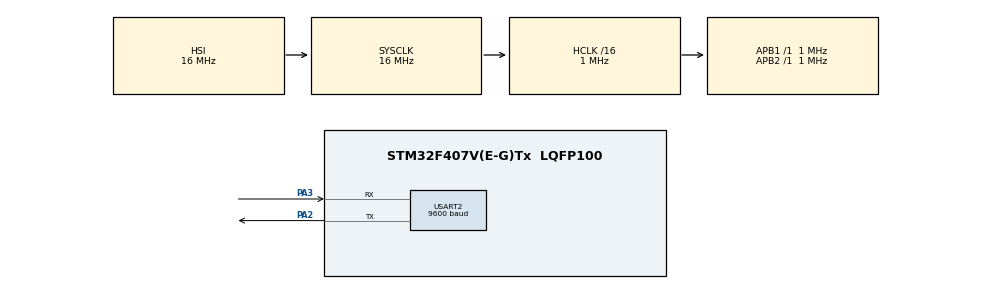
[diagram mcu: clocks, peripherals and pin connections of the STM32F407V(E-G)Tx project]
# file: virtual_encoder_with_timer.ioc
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Mcu.Family=STM32F4
Mcu.Name=STM32F407V(E-G)Tx
Mcu.Package=LQFP100
NVIC.PriorityGroup=NVIC_PRIORITYGROUP_4
NVIC.TIM4_IRQn=true\:0\:0\:false\:true\:true\:1\:true\:true\:true
NVIC.TIM6_DAC_IRQn=true\:0\:0\:false\:true\:true\:2\:true\:true\:true
NVIC.USART2_IRQn=true\:0\:0\:false\:true\:true\:3\:true\:true\:true
PA13.Mode=Serial_Wire
PA13.Signal=SYS_JTMS-SWDIO
PA14.Mode=Serial_Wire
PA14.Signal=SYS_JTCK-SWCLK
PA2.Mode=Asynchronous
PA2.Signal=USART2_TX
PA3.Mode=Asynchronous
PA3.Signal=USART2_RX
ProjectManager.HeapSize=0x200
ProjectManager.StackSize=0x400
ProjectManager.TargetToolchain=STM32CubeIDE
RCC.AHBCLKDivider=RCC_SYSCLK_DIV16
RCC.AHBFreq_Value=1000000
RCC.APB1Freq_Value=1000000
RCC.APB1TimFreq_Value=1000000
RCC.APB2Freq_Value=1000000
RCC.APB2TimFreq_Value=1000000
RCC.CortexFreq_Value=1000000
RCC.HCLKFreq_Value=1000000
RCC.HSE_VALUE=25000000
RCC.HSI_VALUE=16000000
RCC.LSE_VALUE=32768
RCC.SYSCLKFreq_VALUE=16000000
RCC.VCOOutputFreq_Value=192000000
TIM4.AutoReloadPreload=TIM_AUTORELOAD_PRELOAD_ENABLE
TIM4.Period=1000 - 1
TIM4.Prescaler=1000 - 1
TIM6.Period=5000 - 1
TIM6.Prescaler=1000 - 1
USART2.BaudRate=9600
USART2.VirtualMode=VM_ASYNC
VP_TIM4_VS_ClockSourceINT.Mode=Internal
VP_TIM6_VS_ClockSourceINT.Mode=Enable_Timer
board=custom

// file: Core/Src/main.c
/* USER CODE BEGIN Header */
/**
  ******************************************************************************
  * @file           : main.c
  * @brief          : Main program body
  ******************************************************************************
  * @attention
  *
  * Copyright (c) 2025 STMicroelectronics.
  * All rights reserved.
  *
  * This software is licensed under terms that can be found in the LICENSE file
  * in the root directory of this software component.
  * If no LICENSE file comes with this software, it is provided AS-IS.
  *
  ******************************************************************************
  */
/* USER CODE END Header */
#include "main.h"

TIM_HandleTypeDef htim4;
TIM_HandleTypeDef htim6;

UART_HandleTypeDef huart2;

/* USER CODE BEGIN PV */
volatile int32_t virtual_encoder_count = 0;
char buffer[50];
uint8_t rx_data;
/* USER CODE END PV */

void SystemClock_Config(void);
static void MX_GPIO_Init(void);
static void MX_TIM4_Init(void);
static void MX_TIM6_Init(void);
static void MX_USART2_UART_Init(void);
static void MX_NVIC_Init(void);

int main(void)
{

  /* MCU Configuration--------------------------------------------------------*/

  /* Reset of all peripherals, Initializes the Flash interface and the Systick. */
  HAL_Init();

  /* Configure the system clock */
  SystemClock_Config();

  /* Initialize all configured peripherals */
  MX_GPIO_Init();
  MX_TIM4_Init();
  MX_TIM6_Init();
  MX_USART2_UART_Init();

  /* Initialize interrupts */
  MX_NVIC_Init();
  /* USER CODE BEGIN 2 */
  HAL_TIM_Base_Start_IT(&htim4);
  HAL_TIM_Base_Start_IT(&htim6);
  HAL_UART_Receive_IT(&huart2, &rx_data, 1);

  /* USER CODE END 2 */

  /* Infinite loop */
  while (1)
  {

  }
}

void SystemClock_Config(void)
{
  RCC_OscInitTypeDef RCC_OscInitStruct = {0};
  RCC_ClkInitTypeDef RCC_ClkInitStruct = {0};

  /** Configure the main internal regulator output voltage
  */
  __HAL_RCC_PWR_CLK_ENABLE();
  __HAL_PWR_VOLTAGESCALING_CONFIG(PWR_REGULATOR_VOLTAGE_SCALE1);

  /** Initializes the RCC Oscillators according to the specified parameters
  * in the RCC_OscInitTypeDef structure.
  */
  RCC_OscInitStruct.OscillatorType = RCC_OSCILLATORTYPE_HSI;
  RCC_OscInitStruct.HSIState = RCC_HSI_ON;
  RCC_OscInitStruct.HSICalibrationValue = RCC_HSICALIBRATION_DEFAULT;
  RCC_OscInitStruct.PLL.PLLState = RCC_PLL_NONE;
  if (HAL_RCC_OscConfig(&RCC_OscInitStruct) != HAL_OK)
  {
    Error_Handler();
  }

  /** Initializes the CPU, AHB and APB buses clocks
  */
  RCC_ClkInitStruct.ClockType = RCC_CLOCKTYPE_HCLK|RCC_CLOCKTYPE_SYSCLK
                              |RCC_CLOCKTYPE_PCLK1|RCC_CLOCKTYPE_PCLK2;
  RCC_ClkInitStruct.SYSCLKSource = RCC_SYSCLKSOURCE_HSI;
  RCC_ClkInitStruct.AHBCLKDivider = RCC_SYSCLK_DIV16;
  RCC_ClkInitStruct.APB1CLKDivider = RCC_HCLK_DIV1;
  RCC_ClkInitStruct.APB2CLKDivider = RCC_HCLK_DIV1;

  if (HAL_RCC_ClockConfig(&RCC_ClkInitStruct, FLASH_LATENCY_0) != HAL_OK)
  {
    Error_Handler();
  }
}

/**
  * @brief NVIC Configuration.
  * @retval None
  */
static void MX_NVIC_Init(void)
{
  /* TIM4_IRQn interrupt configuration */
  HAL_NVIC_SetPriority(TIM4_IRQn, 0, 0);
  HAL_NVIC_EnableIRQ(TIM4_IRQn);
  /* TIM6_DAC_IRQn interrupt configuration */
  HAL_NVIC_SetPriority(TIM6_DAC_IRQn, 0, 0);
  HAL_NVIC_EnableIRQ(TIM6_DAC_IRQn);
  /* USART2_IRQn interrupt configuration */
  HAL_NVIC_SetPriority(USART2_IRQn, 0, 0);
  HAL_NVIC_EnableIRQ(USART2_IRQn);
}

static void MX_TIM4_Init(void)
{

  TIM_ClockConfigTypeDef sClockSourceConfig = {0};
  TIM_MasterConfigTypeDef sMasterConfig = {0};

  htim4.Instance = TIM4;
  htim4.Init.Prescaler = 1000 - 1;
  htim4.Init.CounterMode = TIM_COUNTERMODE_UP;
  htim4.Init.Period = 1000 - 1;
  htim4.Init.ClockDivision = TIM_CLOCKDIVISION_DIV1;
  htim4.Init.AutoReloadPreload = TIM_AUTORELOAD_PRELOAD_ENABLE;
  if (HAL_TIM_Base_Init(&htim4) != HAL_OK)
  {
    Error_Handler();
  }
  sClockSourceConfig.ClockSource = TIM_CLOCKSOURCE_INTERNAL;
  if (HAL_TIM_ConfigClockSource(&htim4, &sClockSourceConfig) != HAL_OK)
  {
    Error_Handler();
  }
  sMasterConfig.MasterOutputTrigger = TIM_TRGO_RESET;
  sMasterConfig.MasterSlaveMode = TIM_MASTERSLAVEMODE_DISABLE;
  if (HAL_TIMEx_MasterConfigSynchronization(&htim4, &sMasterConfig) != HAL_OK)
  {
    Error_Handler();
  }

}

static void MX_TIM6_Init(void)
{

  TIM_MasterConfigTypeDef sMasterConfig = {0};

  htim6.Instance = TIM6;
  htim6.Init.Prescaler = 1000 - 1;
  htim6.Init.CounterMode = TIM_COUNTERMODE_UP;
  htim6.Init.Period = 5000 - 1;
  htim6.Init.AutoReloadPreload = TIM_AUTORELOAD_PRELOAD_DISABLE;
  if (HAL_TIM_Base_Init(&htim6) != HAL_OK)
  {
    Error_Handler();
  }
  sMasterConfig.MasterOutputTrigger = TIM_TRGO_RESET;
  sMasterConfig.MasterSlaveMode = TIM_MASTERSLAVEMODE_DISABLE;
  if (HAL_TIMEx_MasterConfigSynchronization(&htim6, &sMasterConfig) != HAL_OK)
  {
    Error_Handler();
  }

}

static void MX_USART2_UART_Init(void)
{

  huart2.Instance = USART2;
  huart2.Init.BaudRate = 9600;
  huart2.Init.WordLength = UART_WORDLENGTH_8B;
  huart2.Init.StopBits = UART_STOPBITS_1;
  huart2.Init.Parity = UART_PARITY_NONE;
  huart2.Init.Mode = UART_MODE_TX_RX;
  huart2.Init.HwFlowCtl = UART_HWCONTROL_NONE;
  huart2.Init.OverSampling = UART_OVERSAMPLING_16;
  if (HAL_UART_Init(&huart2) != HAL_OK)
  {
    Error_Handler();
  }

}

static void MX_GPIO_Init(void)
{

  /* GPIO Ports Clock Enable */
  __HAL_RCC_GPIOA_CLK_ENABLE();

}

/* USER CODE BEGIN 4 */
void HAL_TIM_PeriodElapsedCallback(TIM_HandleTypeDef *htim) {
    if (htim->Instance == TIM4) {
    	virtual_encoder_count++;
    } else if (htim->Instance == TIM6) {
    	snprintf(buffer, sizeof(buffer), "COUNT:%ld\n", virtual_encoder_count);
    	HAL_UART_Transmit(&huart2, (uint8_t*)buffer, strlen(buffer), HAL_MAX_DELAY);
    }
}

/* USER CODE END 4 */

void Error_Handler(void)
{
  __disable_irq();
  while (1)
  {
  }
}
